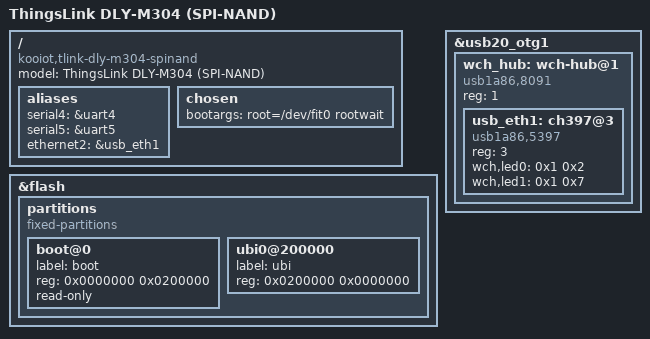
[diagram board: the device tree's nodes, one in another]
// SPDX-License-Identifier: (GPL-2.0+ OR MIT)
/*
 * Copyright (c) 2026 KooIoT.com
 */

/dts-v1/;

#include "rk3506-vx-hd-rk3506g-m-v1.dtsi"

/ {
	model = "ThingsLink DLY-M304 (SPI-NAND)";
	compatible = "kooiot,tlink-dly-m304-spinand", "rockchip,rk3506";

	aliases {
		serial4 = &uart4;
		serial5 = &uart5;
		ethernet2 = &usb_eth1;
	};

	chosen {
		bootargs = "root=/dev/fit0 rootwait";
	};
};

&flash {
	partitions {
		compatible = "fixed-partitions";
		#address-cells = <1>;
		#size-cells = <1>;
		boot@0 {
			label = "boot";
			reg = <0x0000000 0x0200000>;
			read-only;
		};

		ubi0@200000 {
			label = "ubi";
			reg = <0x0200000 0x0000000>;
		};
	};
};

&usb20_otg1 {
	status = "okay";
	#address-cells = <1>;
	#size-cells = <0>;

	wch_hub: wch-hub@1 {
		compatible = "usb1a86,8091";
		reg = <1>;
		#address-cells = <1>;
		#size-cells = <0>;

		usb_eth1: ch397@3 {
			compatible = "usb1a86,5397";
			reg = <3>;
			wch,led0 = <0x1 0x2>;
			wch,led1 = <0x1 0x7>;
		};
	};
};
